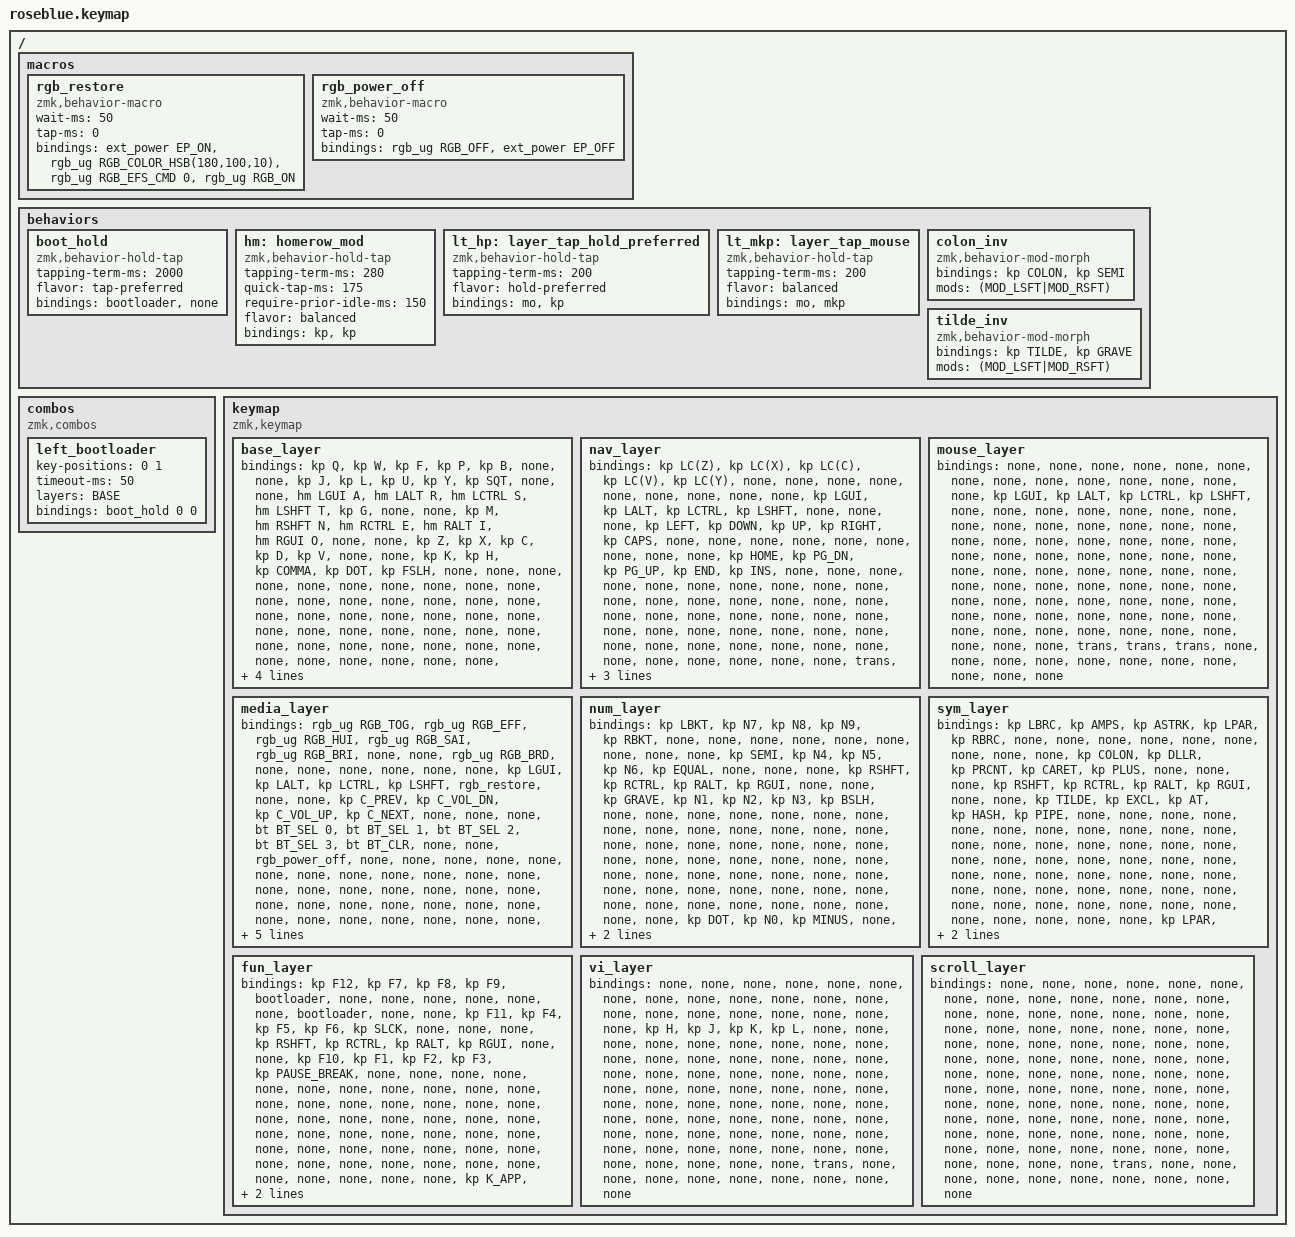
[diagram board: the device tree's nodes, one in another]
/*
 * Miryoku ZMK Layout for Cosmos Lemon Wireless
 * https://github.com/manna-harbour/miryoku
 *
 * Colemak-DH + GACS home row mods
 * 9 layers: Base, Nav, Mouse, Media, Num, Sym, Fun, Vi, Scroll
 */

#include <behaviors.dtsi>
#include <dt-bindings/zmk/keys.h>
#include <dt-bindings/zmk/bt.h>
#include <dt-bindings/zmk/rgb.h>
#include <dt-bindings/zmk/outputs.h>
#include <dt-bindings/zmk/ext_power.h>
#include <dt-bindings/zmk/pointing.h>

#define BASE 0
#define NAV  1
#define MOUSE 2
#define MEDIA 3
#define NUM  4
#define SYM  5
#define FUN  6
#define VI   7
#define SCROLL 8

/ {
    macros {
        // Recover independently saved LED-power and RGB state on both halves.
        // RGB_ON saves the solid 10% preset after the other settings are applied.
        rgb_restore: rgb_restore {
            compatible = "zmk,behavior-macro";
            #binding-cells = <0>;
            wait-ms = <50>;
            tap-ms = <0>;
            bindings = <&ext_power EP_ON>,
                       <&rgb_ug RGB_COLOR_HSB(180,100,10)>,
                       <&rgb_ug RGB_EFS_CMD 0>,
                       <&rgb_ug RGB_ON>;
        };
        // Stop RGB updates before cutting its separate power supply.
        rgb_power_off: rgb_power_off {
            compatible = "zmk,behavior-macro";
            #binding-cells = <0>;
            wait-ms = <50>;
            tap-ms = <0>;
            bindings = <&rgb_ug RGB_OFF>, <&ext_power EP_OFF>;
        };
    };

    behaviors {
        // A short chord cancels; hold both left keys for two seconds to boot.
        boot_hold: boot_hold {
            compatible = "zmk,behavior-hold-tap";
            #binding-cells = <2>;
            tapping-term-ms = <2000>;
            flavor = "tap-preferred";
            bindings = <&bootloader>, <&none>;
        };
        hm: homerow_mod {
            compatible = "zmk,behavior-hold-tap";
            #binding-cells = <2>;
            tapping-term-ms = <280>;
            quick-tap-ms = <175>;
            require-prior-idle-ms = <150>;
            flavor = "balanced";
            bindings = <&kp>, <&kp>;
        };
        lt_hp: layer_tap_hold_preferred {
            compatible = "zmk,behavior-hold-tap";
            #binding-cells = <2>;
            tapping-term-ms = <200>;
            flavor = "hold-preferred";
            bindings = <&mo>, <&kp>;
        };
        lt_mkp: layer_tap_mouse {
            compatible = "zmk,behavior-hold-tap";
            #binding-cells = <2>;
            tapping-term-ms = <200>;
            flavor = "balanced";
            bindings = <&mo>, <&mkp>;
        };
        // Inverted colon: : normally, ; when shifted
        colon_inv: colon_inv {
            compatible = "zmk,behavior-mod-morph";
            #binding-cells = <0>;
            bindings = <&kp COLON>, <&kp SEMI>;
            mods = <(MOD_LSFT|MOD_RSFT)>;
        };
        // Inverted tilde: ~ normally, ` when shifted
        tilde_inv: tilde_inv {
            compatible = "zmk,behavior-mod-morph";
            #binding-cells = <0>;
            bindings = <&kp TILDE>, <&kp GRAVE>;
            mods = <(MOD_LSFT|MOD_RSFT)>;
        };
    };

    combos {
        compatible = "zmk,combos";

        left_bootloader {
            // First two top-row keys: Q + W on the Colemak-DH base layer.
            key-positions = <0 1>;
            timeout-ms = <50>;
            layers = <BASE>;
            bindings = <&boot_hold 0 0>;
        };
    };

    keymap {
        compatible = "zmk,keymap";

        // Layer 0: Base - Colemak-DH
        base_layer {
            bindings = <
                // Row 0
                &kp Q      &kp W      &kp F      &kp P      &kp B      &none      &none
                &kp J      &kp L      &kp U      &kp Y      &kp SQT    &none      &none
                // Row 1 - Home row mods (GACS)
                &hm LGUI A &hm LALT R &hm LCTRL S &hm LSHFT T &kp G    &none      &none
                &kp M      &hm RSHFT N &hm RCTRL E &hm RALT I &hm RGUI O &none    &none
                // Row 2
                &kp Z      &kp X      &kp C      &kp D      &kp V      &none &none
                &kp K      &kp H      &kp COMMA  &kp DOT    &kp FSLH   &none &none
                // Row 3 - Unused: roseblue has a 5 x 3 main grid on each side.
                &none      &none      &none      &none      &none      &none      &none
                &none      &none      &none      &none      &none      &none      &none
                // Row 4
                &none      &none      &none      &none      &none      &none      &none
                &none      &none      &none      &none      &none      &none      &none
                // Row 5
                &none      &none      &none      &none      &none      &none      &none
                &none      &none      &none      &none      &none      &none      &none
                // Row 6 - Thumbs: Esc/Media, Space/Nav, Tab/Mouse | Del/Fun, Enter/Sym, Bspc/Num
                &lt MEDIA ESC &lt NAV SPACE &lt MOUSE TAB &lt_mkp SCROLL RCLK &lt_hp VI SPACE &mkp LCLK &none
                &lt FUN DEL &lt SYM RET &lt NUM BSPC &none  &none      &none      &none
            >;
        };

        // Layer 1: Nav - Navigation & Editing
        nav_layer {
            bindings = <
                // Row 0 - Clipboard
                &kp LC(Z)  &kp LC(X)  &kp LC(C)  &kp LC(V)  &kp LC(Y)  &none      &none
                &none      &none      &none      &none      &none      &none      &none
                // Row 1 - Home row mods (transparent) | Arrows
                &kp LGUI   &kp LALT   &kp LCTRL  &kp LSHFT  &none      &none      &none
                &kp LEFT   &kp DOWN   &kp UP     &kp RIGHT  &kp CAPS   &none      &none
                // Row 2 | Home/End, PgUp/Dn
                &none      &none      &none      &none      &none      &none      &none
                &kp HOME   &kp PG_DN  &kp PG_UP  &kp END    &kp INS    &none      &none
                // Row 3
                &none      &none      &none      &none      &none      &none      &none
                &none      &none      &none      &none      &none      &none      &none
                // Row 4
                &none      &none      &none      &none      &none      &none      &none
                &none      &none      &none      &none      &none      &none      &none
                // Row 5
                &none      &none      &none      &none      &none      &none      &none
                &none      &none      &none      &none      &none      &none      &none
                // Row 6 - Thumbs (Nav held)
                &trans     &trans     &trans     &none      &none      &none      &none
                &kp DEL    &kp RET    &kp BSPC   &none      &none      &none      &none
            >;
        };

        // Layer 2: Mouse (placeholder - ZMK mouse support varies)
        mouse_layer {
            bindings = <
                // Row 0
                &none      &none      &none      &none      &none      &none      &none
                &none      &none      &none      &none      &none      &none      &none
                // Row 1
                &kp LGUI   &kp LALT   &kp LCTRL  &kp LSHFT  &none      &none      &none
                &none      &none      &none      &none      &none      &none      &none
                // Row 2
                &none      &none      &none      &none      &none      &none      &none
                &none      &none      &none      &none      &none      &none      &none
                // Row 3
                &none      &none      &none      &none      &none      &none      &none
                &none      &none      &none      &none      &none      &none      &none
                // Row 4
                &none      &none      &none      &none      &none      &none      &none
                &none      &none      &none      &none      &none      &none      &none
                // Row 5
                &none      &none      &none      &none      &none      &none      &none
                &none      &none      &none      &none      &none      &none      &none
                // Row 6
                &trans     &trans     &trans     &none      &none      &none      &none
                &none      &none      &none      &none      &none      &none      &none
            >;
        };

        // Layer 3: Media
        media_layer {
            bindings = <
                // Row 0 - RGB
                &rgb_ug RGB_TOG &rgb_ug RGB_EFF &rgb_ug RGB_HUI &rgb_ug RGB_SAI &rgb_ug RGB_BRI &none &none
                &rgb_ug RGB_BRD &none &none     &none      &none      &none      &none
                // Row 1 - G restores LED power and solid cyan at 10% on both halves.
                &kp LGUI   &kp LALT   &kp LCTRL  &kp LSHFT  &rgb_restore &none &none
                &kp C_PREV &kp C_VOL_DN &kp C_VOL_UP &kp C_NEXT &none  &none      &none
                // Row 2 - BT | K cuts LED power on both halves.
                &bt BT_SEL 0 &bt BT_SEL 1 &bt BT_SEL 2 &bt BT_SEL 3 &bt BT_CLR &none &none
                &rgb_power_off &none  &none      &none      &none      &none      &none
                // Row 3
                &none      &none      &none      &none      &none      &none      &none
                &none      &none      &none      &none      &none      &none      &none
                // Row 4
                &none      &none      &none      &none      &none      &none      &none
                &none      &none      &none      &none      &none      &none      &none
                // Row 5
                &none      &none      &none      &none      &none      &none      &none
                &none      &none      &none      &none      &none      &none      &none
                // Row 6
                &trans     &trans     &trans     &none      &none      &none      &none
                &kp C_STOP &kp C_PP   &kp C_MUTE &none      &none      &none      &none
            >;
        };

        // Layer 4: Num - Numpad
        num_layer {
            bindings = <
                // Row 0 - Symbols
                &kp LBKT   &kp N7     &kp N8     &kp N9     &kp RBKT   &none      &none
                &none      &none      &none      &none      &none      &none      &none
                // Row 1
                &kp SEMI   &kp N4     &kp N5     &kp N6     &kp EQUAL  &none      &none
                &none      &kp RSHFT  &kp RCTRL  &kp RALT   &kp RGUI   &none      &none
                // Row 2
                &kp GRAVE  &kp N1     &kp N2     &kp N3     &kp BSLH   &none      &none
                &none      &none      &none      &none      &none      &none      &none
                // Row 3
                &none      &none      &none      &none      &none      &none      &none
                &none      &none      &none      &none      &none      &none      &none
                // Row 4
                &none      &none      &none      &none      &none      &none      &none
                &none      &none      &none      &none      &none      &none      &none
                // Row 5
                &none      &none      &none      &none      &none      &none      &none
                &none      &none      &none      &none      &none      &none      &none
                // Row 6
                &kp DOT    &kp N0     &kp MINUS  &none      &none      &none      &none
                &trans     &trans     &trans     &none      &none      &none      &none
            >;
        };

        // Layer 5: Sym - Symbols (shifted num positions)
        sym_layer {
            bindings = <
                // Row 0
                &kp LBRC   &kp AMPS   &kp ASTRK  &kp LPAR   &kp RBRC   &none      &none
                &none      &none      &none      &none      &none      &none      &none
                // Row 1
                &kp COLON  &kp DLLR   &kp PRCNT  &kp CARET  &kp PLUS   &none      &none
                &none      &kp RSHFT  &kp RCTRL  &kp RALT   &kp RGUI   &none      &none
                // Row 2
                &kp TILDE  &kp EXCL   &kp AT     &kp HASH   &kp PIPE   &none      &none
                &none      &none      &none      &none      &none      &none      &none
                // Row 3
                &none      &none      &none      &none      &none      &none      &none
                &none      &none      &none      &none      &none      &none      &none
                // Row 4
                &none      &none      &none      &none      &none      &none      &none
                &none      &none      &none      &none      &none      &none      &none
                // Row 5
                &none      &none      &none      &none      &none      &none      &none
                &none      &none      &none      &none      &none      &none      &none
                // Row 6
                &kp LPAR   &kp RPAR   &kp UNDER  &none      &none      &none      &none
                &trans     &trans     &trans     &none      &none      &none      &none
            >;
        };

        // Layer 6: Fun - Function keys
        fun_layer {
            bindings = <
                // Row 0
                &kp F12    &kp F7     &kp F8     &kp F9     &bootloader &none     &none
                &none      &none      &none      &none      &bootloader &none     &none
                // Row 1
                &kp F11    &kp F4     &kp F5     &kp F6     &kp SLCK   &none      &none
                &none      &kp RSHFT  &kp RCTRL  &kp RALT   &kp RGUI   &none      &none
                // Row 2
                &kp F10    &kp F1     &kp F2     &kp F3     &kp PAUSE_BREAK &none &none
                &none      &none      &none      &none      &none      &none      &none
                // Row 3
                &none      &none      &none      &none      &none      &none      &none
                &none      &none      &none      &none      &none      &none      &none
                // Row 4
                &none      &none      &none      &none      &none      &none      &none
                &none      &none      &none      &none      &none      &none      &none
                // Row 5
                &none      &none      &none      &none      &none      &none      &none
                &none      &none      &none      &none      &none      &none      &none
                // Row 6
                &kp K_APP  &kp SPACE  &kp TAB    &none      &none      &none      &none
                &trans     &trans     &trans     &none      &none      &none      &none
            >;
        };

        // Layer 7: Vi - Arrow keys at HJKL home row positions
        vi_layer {
            bindings = <
                // Row 0
                &none      &none      &none      &none      &none      &none      &none
                &none      &none      &none      &none      &none      &none      &none
                // Row 1 - HJKL arrows on right home row
                &none      &none      &none      &none      &none      &none      &none
                &kp H      &kp J      &kp K      &kp L      &none      &none      &none
                // Row 2
                &none      &none      &none      &none      &none      &none      &none
                &none      &none      &none      &none      &none      &none      &none
                // Row 3
                &none      &none      &none      &none      &none      &none      &none
                &none      &none      &none      &none      &none      &none      &none
                // Row 4
                &none      &none      &none      &none      &none      &none      &none
                &none      &none      &none      &none      &none      &none      &none
                // Row 5
                &none      &none      &none      &none      &none      &none      &none
                &none      &none      &none      &none      &none      &none      &none
                // Row 6 - mo VI held from base
                &none      &none      &none      &none      &trans     &none      &none
                &none      &none      &none      &none      &none      &none      &none
            >;
        };

        // Layer 8: Scroll - Trackball scroll mode (hold 6,3)
        scroll_layer {
            bindings = <
                // Row 0
                &none      &none      &none      &none      &none      &none      &none
                &none      &none      &none      &none      &none      &none      &none
                // Row 1
                &none      &none      &none      &none      &none      &none      &none
                &none      &none      &none      &none      &none      &none      &none
                // Row 2
                &none      &none      &none      &none      &none      &none      &none
                &none      &none      &none      &none      &none      &none      &none
                // Row 3
                &none      &none      &none      &none      &none      &none      &none
                &none      &none      &none      &none      &none      &none      &none
                // Row 4
                &none      &none      &none      &none      &none      &none      &none
                &none      &none      &none      &none      &none      &none      &none
                // Row 5
                &none      &none      &none      &none      &none      &none      &none
                &none      &none      &none      &none      &none      &none      &none
                // Row 6 - Hold passes through
                &none      &none      &none      &trans     &none      &none      &none
                &none      &none      &none      &none      &none      &none      &none
            >;
        };
    };
};
